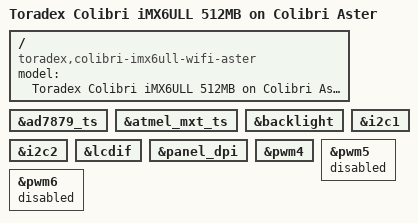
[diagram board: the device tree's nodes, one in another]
/dts-v1/;
#include "imx6ull-colibri-wifi.dtsi"
#include "imx6ull-colibri-aster.dtsi"
/ {
	model = "Toradex Colibri iMX6ULL 512MB on Colibri Aster";
	compatible = "toradex,colibri-imx6ull-wifi-aster",
		     "toradex,colibri-imx6ull",
		     "fsl,imx6ull";
};
&ad7879_ts {
	status = "okay";
};
&atmel_mxt_ts {
	status = "okay";
};
&backlight {
	status = "okay";
};
&i2c1 {
	status = "okay";
};
&i2c2 {
	status = "okay";
};
&lcdif {
	status = "okay";
};
&panel_dpi {
	status = "okay";
};
&pwm4 {
	status = "okay";
};
&pwm5 {
	status = "disabled";
};
&pwm6 {
	status = "disabled";
};
